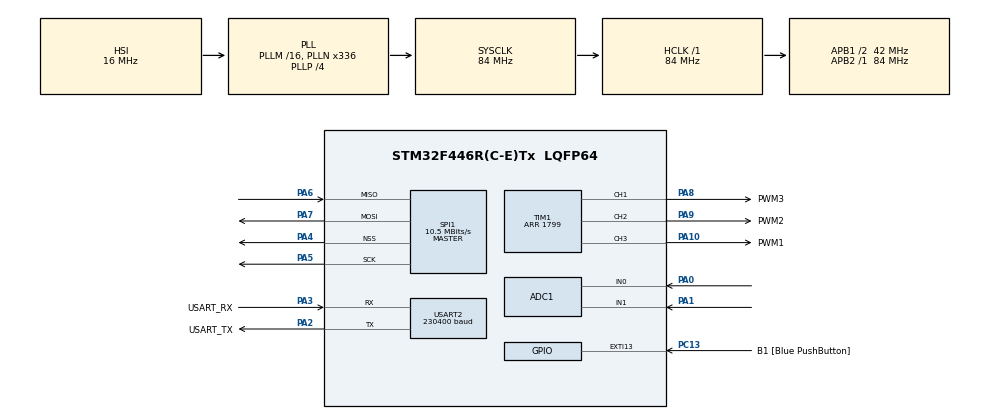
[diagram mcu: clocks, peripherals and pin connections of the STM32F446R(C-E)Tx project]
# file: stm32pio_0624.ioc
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ADC1.Channel-0\#ChannelRegularConversion=ADC_CHANNEL_0
ADC1.ContinuousConvMode=ENABLE
ADC1.InjNumberOfConversion=0
ADC1.NbrOfConversionFlag=1
ADC1.Rank-0\#ChannelRegularConversion=1
ADC1.SamplingTime-0\#ChannelRegularConversion=ADC_SAMPLETIME_3CYCLES
ADC1.ScanConvMode=ENABLE
ADC1.master=1
Mcu.Family=STM32F4
Mcu.Name=STM32F446R(C-E)Tx
Mcu.Package=LQFP64
NVIC.PriorityGroup=NVIC_PRIORITYGROUP_0
PA0-WKUP.Signal=ADCx_IN0
PA1.Signal=ADCx_IN1
PA10.GPIO_Label=PWM1
PA10.Signal=S_TIM1_CH3
PA13.GPIO_Label=TMS
PA13.Mode=Serial_Wire
PA13.Signal=SYS_JTMS-SWDIO
PA14.GPIO_Label=TCK
PA14.Mode=Serial_Wire
PA14.Signal=SYS_JTCK-SWCLK
PA2.GPIO_Label=USART_TX
PA2.Mode=Asynchronous
PA2.Signal=USART2_TX
PA3.GPIO_Label=USART_RX
PA3.Mode=Asynchronous
PA3.Signal=USART2_RX
PA4.Mode=NSS_Signal_Hard_Output
PA4.Signal=SPI1_NSS
PA5.Mode=Full_Duplex_Master
PA5.Signal=SPI1_SCK
PA6.Mode=Full_Duplex_Master
PA6.Signal=SPI1_MISO
PA7.Mode=Full_Duplex_Master
PA7.Signal=SPI1_MOSI
PA8.GPIO_Label=PWM3
PA8.Signal=S_TIM1_CH1
PA9.GPIO_Label=PWM2
PA9.Signal=S_TIM1_CH2
PB3.GPIO_Label=SWO
PB3.Signal=SYS_JTDO-SWO
PC13.GPIO_Label=B1 [Blue PushButton]
PC13.GPIO_ModeDefaultEXTI=GPIO_MODE_IT_FALLING
PC13.Signal=GPXTI13
PC14-OSC32_IN.Mode=LSE-External-Oscillator
PC14-OSC32_IN.Signal=RCC_OSC32_IN
PC15-OSC32_OUT.Mode=LSE-External-Oscillator
PC15-OSC32_OUT.Signal=RCC_OSC32_OUT
PH0-OSC_IN.Mode=HSE-External-Oscillator
PH0-OSC_IN.Signal=RCC_OSC_IN
PH1-OSC_OUT.Mode=HSE-External-Oscillator
PH1-OSC_OUT.Signal=RCC_OSC_OUT
ProjectManager.HeapSize=0x200
ProjectManager.StackSize=0x400
ProjectManager.TargetToolchain=Other Toolchains (GPDSC)
RCC.48MHZClocksFreq_Value=84000000
RCC.AHBFreq_Value=84000000
RCC.APB1CLKDivider=RCC_HCLK_DIV2
RCC.APB1Freq_Value=42000000
RCC.APB1TimFreq_Value=84000000
RCC.APB2Freq_Value=84000000
RCC.APB2TimFreq_Value=84000000
RCC.CortexFreq_Value=84000000
RCC.FLatency-AdvancedSettings=FLASH_LATENCY_2
RCC.HCLKFreq_Value=84000000
RCC.HSE_VALUE=8000000
RCC.HSI_VALUE=16000000
RCC.PLLN=336
RCC.PLLP=RCC_PLLP_DIV4
RCC.SYSCLKFreq_VALUE=84000000
RCC.SYSCLKSource=RCC_SYSCLKSOURCE_PLLCLK
RCC.USBFreq_Value=168000000
RCC.VCOOutputFreq_Value=336000000
SH.ADCx_IN0.0=ADC1_IN0,IN0
SH.ADCx_IN1.0=ADC1_IN1,IN1
SH.S_TIM1_CH1.0=TIM1_CH1,PWM Generation1 CH1
SH.S_TIM1_CH2.0=TIM1_CH2,PWM Generation2 CH2
SH.S_TIM1_CH3.0=TIM1_CH3,PWM Generation3 CH3
SPI1.BaudRatePrescaler=SPI_BAUDRATEPRESCALER_8
SPI1.CalculateBaudRate=10.5 MBits/s
SPI1.Direction=SPI_DIRECTION_2LINES
SPI1.Mode=SPI_MODE_MASTER
SPI1.VirtualNSS=VM_NSSHARD
SPI1.VirtualType=VM_MASTER
TIM1.AutoReloadPreload=TIM_AUTORELOAD_PRELOAD_ENABLE
TIM1.Channel-PWM\ Generation1\ CH1=TIM_CHANNEL_1
TIM1.Channel-PWM\ Generation2\ CH2=TIM_CHANNEL_2
TIM1.Channel-PWM\ Generation3\ CH3=TIM_CHANNEL_3
TIM1.OCFastMode_PWM-PWM\ Generation1\ CH1=TIM_OCFAST_ENABLE
TIM1.OCFastMode_PWM-PWM\ Generation2\ CH2=TIM_OCFAST_ENABLE
TIM1.OCFastMode_PWM-PWM\ Generation3\ CH3=TIM_OCFAST_ENABLE
TIM1.Period=1799
USART2.BaudRate=230400
USART2.VirtualMode=VM_ASYNC
board=NUCLEO-F446RE

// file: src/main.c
/* USER CODE BEGIN Header */
/**
 ******************************************************************************
 * @file           : main.c
 * @brief          : Main program body
 ******************************************************************************
 * @attention
 *
 * <h2><center>&copy; Copyright (c) 2023 STMicroelectronics.
 * All rights reserved.</center></h2>
 *
 * This software component is licensed by ST under BSD 3-Clause license,
 * the "License"; You may not use this file except in compliance with the
 * License. You may obtain a copy of the License at:
 *                        opensource.org/licenses/BSD-3-Clause
 *
 ******************************************************************************
 */
/* USER CODE END Header */
#include "main.h"
#include "adc.h"
#include "spi.h"
#include "tim.h"
#include "usart.h"
#include "gpio.h"

/* USER CODE BEGIN Includes */
#include <alt_main.hpp>
/* USER CODE END Includes */

void SystemClock_Config(void);

/* USER CODE BEGIN 0 */
int _write(int file, char *ptr, int len) {
    HAL_UART_Transmit(&huart2, (uint8_t *)ptr, len, 10);
    return len;
}
/* USER CODE END 0 */

int main(void) {
    /* USER CODE BEGIN 1 */
    setbuf(stdout, NULL);
    /* USER CODE END 1 */

    /* MCU Configuration--------------------------------------------------------*/

    /* Reset of all peripherals, Initializes the Flash interface and the Systick. */
    HAL_Init();

    /* Configure the system clock */
    SystemClock_Config();

    /* Initialize all configured peripherals */
    MX_GPIO_Init();
    MX_ADC1_Init();
    MX_SPI1_Init();
    MX_TIM1_Init();
    MX_USART2_UART_Init();

    /* Infinite loop */
    /* USER CODE BEGIN WHILE */
    alt_main();
    while (1) {
        /* USER CODE END WHILE */

    }
}

void SystemClock_Config(void) {
    RCC_OscInitTypeDef RCC_OscInitStruct = {0};
    RCC_ClkInitTypeDef RCC_ClkInitStruct = {0};

    /** Configure the main internal regulator output voltage
     */
    __HAL_RCC_PWR_CLK_ENABLE();
    __HAL_PWR_VOLTAGESCALING_CONFIG(PWR_REGULATOR_VOLTAGE_SCALE3);
    /** Initializes the RCC Oscillators according to the specified parameters
     * in the RCC_OscInitTypeDef structure.
     */
    RCC_OscInitStruct.OscillatorType = RCC_OSCILLATORTYPE_HSI;
    RCC_OscInitStruct.HSIState = RCC_HSI_ON;
    RCC_OscInitStruct.HSICalibrationValue = RCC_HSICALIBRATION_DEFAULT;
    RCC_OscInitStruct.PLL.PLLState = RCC_PLL_ON;
    RCC_OscInitStruct.PLL.PLLSource = RCC_PLLSOURCE_HSI;
    RCC_OscInitStruct.PLL.PLLM = 16;
    RCC_OscInitStruct.PLL.PLLN = 336;
    RCC_OscInitStruct.PLL.PLLP = RCC_PLLP_DIV4;
    RCC_OscInitStruct.PLL.PLLQ = 2;
    RCC_OscInitStruct.PLL.PLLR = 2;
    if (HAL_RCC_OscConfig(&RCC_OscInitStruct) != HAL_OK) {
        Error_Handler();
    }
    /** Initializes the CPU, AHB and APB buses clocks
     */
    RCC_ClkInitStruct.ClockType = RCC_CLOCKTYPE_HCLK | RCC_CLOCKTYPE_SYSCLK | RCC_CLOCKTYPE_PCLK1 | RCC_CLOCKTYPE_PCLK2;
    RCC_ClkInitStruct.SYSCLKSource = RCC_SYSCLKSOURCE_PLLCLK;
    RCC_ClkInitStruct.AHBCLKDivider = RCC_SYSCLK_DIV1;
    RCC_ClkInitStruct.APB1CLKDivider = RCC_HCLK_DIV2;
    RCC_ClkInitStruct.APB2CLKDivider = RCC_HCLK_DIV1;

    if (HAL_RCC_ClockConfig(&RCC_ClkInitStruct, FLASH_LATENCY_2) != HAL_OK) {
        Error_Handler();
    }
}

void Error_Handler(void) {
    __disable_irq();
    while (1) {
    }
}

/************************ (C) COPYRIGHT STMicroelectronics *****END OF FILE****/
